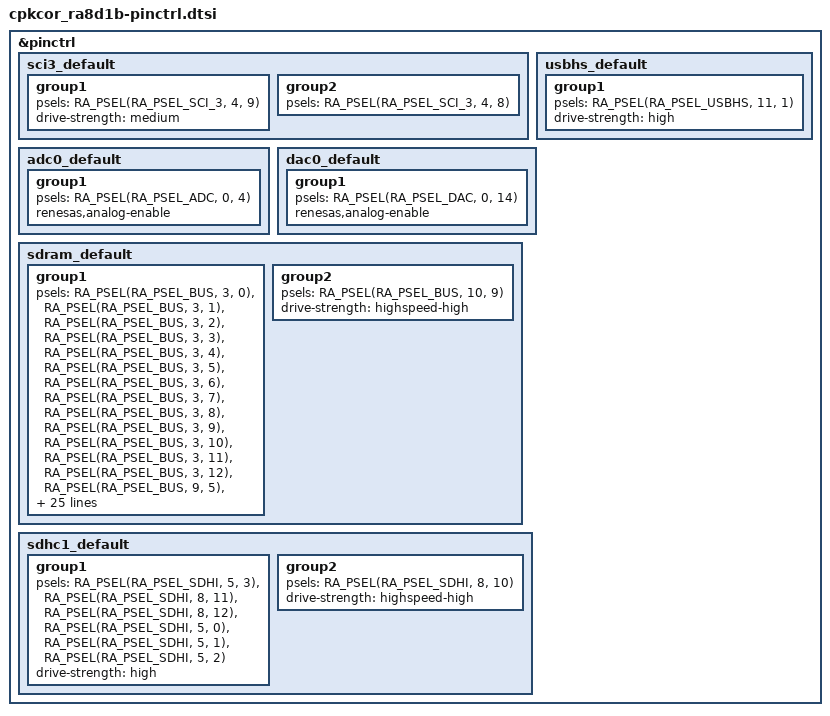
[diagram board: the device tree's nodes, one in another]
/*
 * Copyright (c) 2025 Renesas Electronics Corporation
 * Copyright (c) 2025 Jisheng Zhang <jszhang@kernel.org>
 * SPDX-License-Identifier: Apache-2.0
 */

&pinctrl {
	sci3_default: sci3_default {
		group1 {
			/* tx */
			psels = <RA_PSEL(RA_PSEL_SCI_3, 4, 9)>;
			drive-strength = "medium";
		};

		group2 {
			/* rx */
			psels = <RA_PSEL(RA_PSEL_SCI_3, 4, 8)>;
		};
	};

	usbhs_default: usbhs_default {
		group1 {
			psels = <RA_PSEL(RA_PSEL_USBHS, 11, 1)>; /* USBHS-VBUS */
			drive-strength = "high";
		};
	};

	adc0_default: adc0_default {
		group1 {
			/* input */
			psels = <RA_PSEL(RA_PSEL_ADC, 0, 4)>;
			renesas,analog-enable;
		};
	};

	dac0_default: dac0_default {
		group1 {
			/* output */
			psels = <RA_PSEL(RA_PSEL_DAC, 0, 14)>;
			renesas,analog-enable;
		};
	};

	sdram_default: sdram_default {
		group1 {
			psels = <RA_PSEL(RA_PSEL_BUS, 3, 0)>, /* SDRAM_A1 */
				<RA_PSEL(RA_PSEL_BUS, 3, 1)>, /* SDRAM_A2 */
				<RA_PSEL(RA_PSEL_BUS, 3, 2)>, /* SDRAM_A3 */
				<RA_PSEL(RA_PSEL_BUS, 3, 3)>, /* SDRAM_A4 */
				<RA_PSEL(RA_PSEL_BUS, 3, 4)>, /* SDRAM_A5 */
				<RA_PSEL(RA_PSEL_BUS, 3, 5)>, /* SDRAM_A6 */
				<RA_PSEL(RA_PSEL_BUS, 3, 6)>, /* SDRAM_A7 */
				<RA_PSEL(RA_PSEL_BUS, 3, 7)>, /* SDRAM_A8 */
				<RA_PSEL(RA_PSEL_BUS, 3, 8)>, /* SDRAM_A9 */
				<RA_PSEL(RA_PSEL_BUS, 3, 9)>, /* SDRAM_A10 */
				<RA_PSEL(RA_PSEL_BUS, 3, 10)>, /* SDRAM_A11 */
				<RA_PSEL(RA_PSEL_BUS, 3, 11)>, /* SDRAM_A12 */
				<RA_PSEL(RA_PSEL_BUS, 3, 12)>, /* SDRAM_A13 */
				<RA_PSEL(RA_PSEL_BUS, 9, 5)>, /* SDRAM_A14 */
				<RA_PSEL(RA_PSEL_BUS, 9, 6)>, /* SDRAM_A15 */
				<RA_PSEL(RA_PSEL_BUS, 9, 9)>, /* SDRAM_CAS */
				<RA_PSEL(RA_PSEL_BUS, 1, 13)>, /* SDRAM_CKE */
				<RA_PSEL(RA_PSEL_BUS, 6, 1)>, /* SDRAM_DQ0 */
				<RA_PSEL(RA_PSEL_BUS, 6, 2)>, /* SDRAM_DQ1 */
				<RA_PSEL(RA_PSEL_BUS, 6, 3)>, /* SDRAM_DQ2 */
				<RA_PSEL(RA_PSEL_BUS, 6, 4)>, /* SDRAM_DQ3 */
				<RA_PSEL(RA_PSEL_BUS, 6, 5)>, /* SDRAM_DQ4 */
				<RA_PSEL(RA_PSEL_BUS, 6, 6)>, /* SDRAM_DQ5 */
				<RA_PSEL(RA_PSEL_BUS, 6, 7)>, /* SDRAM_DQ6 */
				<RA_PSEL(RA_PSEL_BUS, 10, 0)>, /* SDRAM_DQ7 */
				<RA_PSEL(RA_PSEL_BUS, 6, 9)>, /* SDRAM_DQ8 */
				<RA_PSEL(RA_PSEL_BUS, 6, 10)>, /* SDRAM_DQ9 */
				<RA_PSEL(RA_PSEL_BUS, 6, 11)>, /* SDRAM_DQ10 */
				<RA_PSEL(RA_PSEL_BUS, 6, 12)>, /* SDRAM_DQ11 */
				<RA_PSEL(RA_PSEL_BUS, 6, 13)>, /* SDRAM_DQ12 */
				<RA_PSEL(RA_PSEL_BUS, 6, 14)>, /* SDRAM_DQ13 */
				<RA_PSEL(RA_PSEL_BUS, 6, 15)>, /* SDRAM_DQ14 */
				<RA_PSEL(RA_PSEL_BUS, 10, 8)>, /* SDRAM_DQ15 */
				<RA_PSEL(RA_PSEL_BUS, 10, 10)>, /* SDRAM_DQM0 */
				<RA_PSEL(RA_PSEL_BUS, 1, 12)>, /* SDRAM_DQM1 */
				<RA_PSEL(RA_PSEL_BUS, 9, 8)>, /* SDRAM_RAS */
				<RA_PSEL(RA_PSEL_BUS, 1, 15)>, /* SDRAM_SDCS */
				<RA_PSEL(RA_PSEL_BUS, 1, 14)>; /* SDRAM_WE */
			drive-strength = "high";
		};

		group2 {
			psels = <RA_PSEL(RA_PSEL_BUS, 10, 9)>; /* SDRAM_SDCLK */
			drive-strength = "highspeed-high";
		};
	};

	sdhc1_default: sdhc1_default {
		group1 {
			psels = <RA_PSEL(RA_PSEL_SDHI, 5, 3)>, /* SDCD */
				<RA_PSEL(RA_PSEL_SDHI, 8, 11)>, /* SDCMD */
				<RA_PSEL(RA_PSEL_SDHI, 8, 12)>, /* SDDATA0 */
				<RA_PSEL(RA_PSEL_SDHI, 5, 0)>, /* SDDATA1 */
				<RA_PSEL(RA_PSEL_SDHI, 5, 1)>, /* SDDATA2 */
				<RA_PSEL(RA_PSEL_SDHI, 5, 2)>; /* SDDATA3 */
			drive-strength = "high";
		};

		group2 {
			psels = <RA_PSEL(RA_PSEL_SDHI, 8, 10)>; /* SDCLK */
			drive-strength = "highspeed-high";
		};
	};
};
